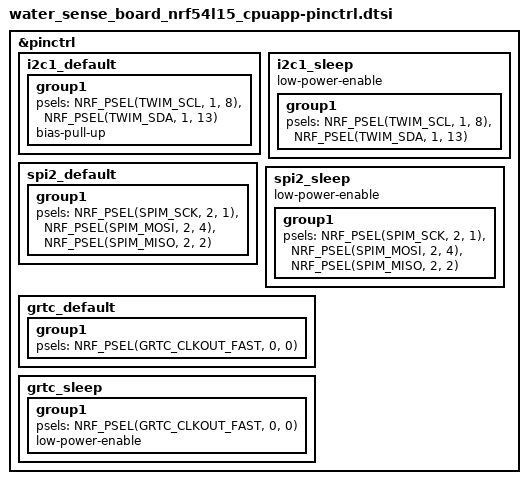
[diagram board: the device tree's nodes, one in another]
/*
 * Pin assignments — all from Victor, unchanged from the original board file
 * except for the AP_CLK group, which is new.
 *
 *   SCL      P1.08      SDA      P1.13
 *   SCK      P2.01      SDI      P2.04      SDO      P2.02
 *   CS       P2.05      — driven in software from the port file, so it is
 *                         deliberately NOT a pinctrl signal. On nRF, chip
 *                         select never is: SPIM does not drive it. That is also
 *                         why CS can sit on P0 while the SPI signals are on P2:
 *                         a plain GPIO has no power-domain tie to the
 *                         peripheral, whereas a pinctrl signal does.
 *   AP_CLK   P0.00      — 8 MHz to the VL53L9CX, from the GRTC fast clock
 *                         output rather than a PWM. Corrected from P0.13,
 *                         which is not a pin on this SoC.
 *
 * SPDX-License-Identifier: Apache-2.0
 */

&pinctrl {

	/*
	 * bias-pull-up added 2026-09-05 at Victor's instruction, as a test.
	 *
	 * The board is believed to have external pull-ups already, so this is
	 * belt and braces — but the evidence says otherwise and it is worth one
	 * boot to find out. Every first I2C transaction returns -ETIMEDOUT,
	 * which means the master could not complete the transfer at all rather
	 * than getting no answer: SDA or SCL never reached a high level. An
	 * absent or unclocked slave cannot cause that, because it drives
	 * nothing. Missing pull-ups can.
	 *
	 * The suspicion is sharpened by history: the LSM6DSV IMU worked on this
	 * bus, at these pins, at 400 kHz — and the bus started hanging after
	 * that part was removed.
	 *
	 * CAVEAT ON WHAT THIS PROVES. The nRF internal pull-ups are weak,
	 * roughly 13 kOhm against the 2.2-4.7 kOhm usual for 400 kHz. If this
	 * fixes it, the external pull-ups are missing or wrong and should be
	 * fitted properly rather than left to the SoC. If it does not fix it,
	 * that is NOT proof the pull-ups are fine — weak ones can still fail to
	 * pull a loaded bus high in time at 400 kHz. The next single-variable
	 * test in that case is 100 kHz, which tolerates far weaker pull-ups.
	 *
	 * Only on the default state, not on sleep: pulling a bus up while the
	 * peripheral is idle costs current for nothing.
	 */
	i2c1_default: i2c1_default {
		group1 {
			psels = <NRF_PSEL(TWIM_SCL, 1, 8)>,
				<NRF_PSEL(TWIM_SDA, 1, 13)>;
			bias-pull-up;
		};
	};

	i2c1_sleep: i2c1_sleep {
		group1 {
			psels = <NRF_PSEL(TWIM_SCL, 1, 8)>,
				<NRF_PSEL(TWIM_SDA, 1, 13)>;
		};
		low-power-enable;
	};

	spi2_default: spi2_default {
		group1 {
			psels = <NRF_PSEL(SPIM_SCK, 2, 1)>,
				<NRF_PSEL(SPIM_MOSI, 2, 4)>,
				<NRF_PSEL(SPIM_MISO, 2, 2)>;
		};
	};

	spi2_sleep: spi2_sleep {
		group1 {
			psels = <NRF_PSEL(SPIM_SCK, 2, 1)>,
				<NRF_PSEL(SPIM_MOSI, 2, 4)>,
				<NRF_PSEL(SPIM_MISO, 2, 2)>;
		};
		low-power-enable;
	};

	/*
	 * AP_CLK — 8 MHz to the VL53L9CX on P0.00, from GRTC.
	 *
	 * NOT a PWM. Two reasons, both checked against the SDK rather than
	 * assumed:
	 *
	 *   - PWM cannot reach port 0. PWM_OUT appears only on P1 across every
	 *     Nordic board in the tree; P0 carries uart30 and GRTC functions.
	 *     P0 is the 30 power domain, pwm20/21/22 are 20-domain.
	 *   - GRTC can. Nordic's own DK routes GRTC_CLKOUT_32K to P0.04, so the
	 *     clock outputs are not confined to P1.
	 *
	 * And GRTC is the better source anyway — see the &grtc node for the
	 * arithmetic. 8 MHz is exactly its maximum, with an integer divider.
	 */
	grtc_default: grtc_default {
		group1 {
			psels = <NRF_PSEL(GRTC_CLKOUT_FAST, 0, 0)>;
		};
	};

	grtc_sleep: grtc_sleep {
		group1 {
			psels = <NRF_PSEL(GRTC_CLKOUT_FAST, 0, 0)>;
			low-power-enable;
		};
	};
};
